# STM32H503 register map
File version: 1.5
CPU: CM33 r0p0, little endian, MPU, FPU, 4 interrupt priority bits
Registers are 32-bit, read-write, reset 0x0 unless marked. A register's access mark holds for its fields unless they carry their own. Offsets are from the block's base; [hi:lo] are bit positions; {n}, {i} and the like mark numbered series.

## CRS — Clock recovery system
Base 0x40006000
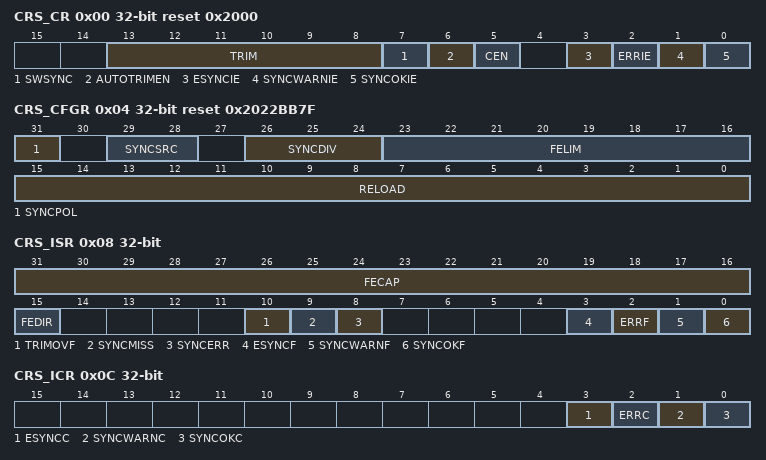
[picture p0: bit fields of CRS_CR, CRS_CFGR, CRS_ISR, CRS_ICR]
0x00 CRS_CR reset 0x2000 — CRS control register
  [13:8] TRIM — HSI48 oscillator smooth trimming These bits provide a user-programmable trimming value to the HSI48 oscillator. They can be programmed to adjust to variations in voltage and temperature that influence the frequency of the HSI48 oscillator. The default value is 32, which corresponds to the middle of the trimming interval. The trimming step is specified in the product datasheet. A higher TRIM value corresponds to a higher output frequency. When the AUTOTRIMEN bit is set, this field is controlled by hardware and is read-only.
  [7] SWSYNC — Generate software SYNC event This bit is set by software in order to generate a software SYNC event. It is automatically cleared by hardware.
    0=No action; 1=A software SYNC event is generated
  [6] AUTOTRIMEN — Automatic trimming enable This bit enables the automatic hardware adjustment of TRIM bits according to the measured frequency error between two SYNC events. If this bit is set, the TRIM bits are read-only. The TRIM value can be adjusted by hardware by one or two steps at a time, depending on the measured frequency error value. Refer to Section 10.5.3 for more details.
    0=Automatic trimming disabled, TRIM bits can be adjusted by the user; 1=Automatic trimming enabled, TRIM bits are read-only and under hardware control
  [5] CEN — Frequency error counter enable This bit enables the oscillator clock for the frequency error counter. When this bit is set, the CRS_CFGR register is write-protected and cannot be modified.
    0=Frequency error counter disabled; 1=Frequency error counter enabled
  [3] ESYNCIE — Expected SYNC interrupt enable
    0=Expected SYNC (ESYNCF) interrupt disabled; 1=Expected SYNC (ESYNCF) interrupt enabled
  [2] ERRIE — Synchronization or trimming error interrupt enable
    0=Synchronization or trimming error (ERRF) interrupt disabled; 1=Synchronization or trimming error (ERRF) interrupt enabled
  [1] SYNCWARNIE — SYNC warning interrupt enable
    0=SYNC warning (SYNCWARNF) interrupt disabled; 1=SYNC warning (SYNCWARNF) interrupt enabled
  [0] SYNCOKIE — SYNC event OK interrupt enable
    0=SYNC event OK (SYNCOKF) interrupt disabled; 1=SYNC event OK (SYNCOKF) interrupt enabled
0x04 CRS_CFGR reset 0x2022BB7F — CRS configuration register
  [31] SYNCPOL — SYNC polarity selection This bit is set and cleared by software to select the input polarity for the SYNC signal source.
    0=SYNC active on rising edge (default); 1=SYNC active on falling edge
  [29:28] SYNCSRC — SYNC signal source selection These bits are set and cleared by software to select the SYNC signal source (see Table 68: CRS internal input/output signals for STM32U575/585): Note: When using USB LPM (Link Power Management) and the device is in Sleep mode, the periodic USB SOF is not generated by the host. No SYNC signal is therefore provided to the CRS to calibrate the HSI48 oscillator on the run. To guarantee the required clock precision after waking up from Sleep mode, the LSE or reference clock on the GPIOs must be used as SYNC signal.
    {v}=crs_sync_in_{v+1} selected as SYNC signal source (v=0..3)
  [26:24] SYNCDIV — SYNC divider These bits are set and cleared by software to control the division factor of the SYNC signal.
    0=SYNC not divided (default); 1=SYNC divided by 2; 2=SYNC divided by 4; 3=SYNC divided by 8; 4=SYNC divided by 16; 5=SYNC divided by 32; 6=SYNC divided by 64; 7=SYNC divided by 128
  [23:16] FELIM — Frequency error limit FELIM contains the value to be used to evaluate the captured frequency error value latched in the FECAP[15:0] bits of the CRS_ISR register. Refer to Section 10.5.3 for more details about FECAP evaluation.
  [15:0] RELOAD — Counter reload value RELOAD is the value to be loaded in the frequency error counter with each SYNC event. Refer to Section 10.5.2 for more details about counter behavior.
0x08 CRS_ISR ro — CRS interrupt and status register
  [31:16] FECAP — Frequency error capture FECAP is the frequency error counter value latched in the time of the last SYNC event. Refer to Section 10.5.3 for more details about FECAP usage.
  [15] FEDIR — Frequency error direction FEDIR is the counting direction of the frequency error counter latched in the time of the last SYNC event. It shows whether the actual frequency is below or above the target.
    0=Upcounting direction, the actual frequency is above the target; 1=Downcounting direction, the actual frequency is below the target
  [10] TRIMOVF — Trimming overflow or underflow This flag is set by hardware when the automatic trimming tries to over- or under-flow the TRIM value. An interrupt is generated if the ERRIE bit is set in the CRS_CR register. It is cleared by software by setting the ERRC bit in the CRS_ICR register.
    0=No trimming error signalized; 1=Trimming error signalized
  [9] SYNCMISS — SYNC missed This flag is set by hardware when the frequency error counter reached value FELIM * 128 and no SYNC was detected, meaning either that a SYNC pulse was missed or that the frequency error is too big (internal frequency too high) to be compensated by adjusting the TRIM value, and that some other action has to be taken. At this point, the frequency error counter is stopped (waiting for a next SYNC) and an interrupt is generated if the ERRIE bit is set in the CRS_CR register. It is cleared by software by setting the ERRC bit in the CRS_ICR register.
    0=No SYNC missed error signalized; 1=SYNC missed error signalized
  [8] SYNCERR — SYNC error This flag is set by hardware when the SYNC pulse arrives before the ESYNC event and the measured frequency error is greater than or equal to FELIM * 128. This means that the frequency error is too big (internal frequency too low) to be compensated by adjusting the TRIM value, and that some other action has to be taken. An interrupt is generated if the ERRIE bit is set in the CRS_CR register. It is cleared by software by setting the ERRC bit in the CRS_ICR register.
    0=No SYNC error signalized; 1=SYNC error signalized
  [3] ESYNCF — Expected SYNC flag This flag is set by hardware when the frequency error counter reached a zero value. An interrupt is generated if the ESYNCIE bit is set in the CRS_CR register. It is cleared by software by setting the ESYNCC bit in the CRS_ICR register.
    0=No expected SYNC signalized; 1=Expected SYNC signalized
  [2] ERRF — Error flag This flag is set by hardware in case of any synchronization or trimming error. It is the logical OR of the TRIMOVF, SYNCMISS and SYNCERR bits. An interrupt is generated if the ERRIE bit is set in the CRS_CR register. It is cleared by software in reaction to setting the ERRC bit in the CRS_ICR register, which clears the TRIMOVF, SYNCMISS and SYNCERR bits.
    0=No synchronization or trimming error signalized; 1=Synchronization or trimming error signalized
  [1] SYNCWARNF — SYNC warning flag This flag is set by hardware when the measured frequency error is greater than or equal to FELIM * 3, but smaller than FELIM * 128. This means that to compensate the frequency error, the TRIM value must be adjusted by two steps or more. An interrupt is generated if the SYNCWARNIE bit is set in the CRS_CR register. It is cleared by software by setting the SYNCWARNC bit in the CRS_ICR register.
    0=No SYNC warning signalized; 1=SYNC warning signalized
  [0] SYNCOKF — SYNC event OK flag This flag is set by hardware when the measured frequency error is smaller than FELIM * 3. This means that either no adjustment of the TRIM value is needed or that an adjustment by one trimming step is enough to compensate the frequency error. An interrupt is generated if the SYNCOKIE bit is set in the CRS_CR register. It is cleared by software by setting the SYNCOKC bit in the CRS_ICR register.
    0=No SYNC event OK signalized; 1=SYNC event OK signalized
0x0C CRS_ICR — CRS interrupt flag clear register
  [3] ESYNCC — Expected SYNC clear flag Writing 1 to this bit clears the ESYNCF flag in the CRS_ISR register.
  [2] ERRC — Error clear flag Writing 1 to this bit clears TRIMOVF, SYNCMISS and SYNCERR bits and consequently also the ERRF flag in the CRS_ISR register.
  [1] SYNCWARNC — SYNC warning clear flag Writing 1 to this bit clears the SYNCWARNF flag in the CRS_ISR register.
  [0] SYNCOKC — SYNC event OK clear flag Writing 1 to this bit clears the SYNCOKF flag in the CRS_ISR register.
